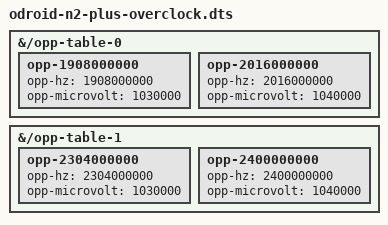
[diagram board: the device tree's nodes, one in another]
/dts-v1/;
/plugin/;

/ {
	fragment@0 {
		target-path = "/opp-table-0";
		__overlay__ {
			opp-1908000000 {
				opp-hz = /bits/ 64 <1908000000>;
				opp-microvolt = <1030000>;
			};
			opp-2016000000 {
				opp-hz = /bits/ 64 <2016000000>;
				opp-microvolt = <1040000>;
			};
		};
	};
	fragment@1 {
		target-path = "/opp-table-1"; 
		__overlay__ {
			opp-2304000000 {
				opp-hz = /bits/ 64 <2304000000>;
				opp-microvolt = <1030000>;
			};
			opp-2400000000 {
				opp-hz = /bits/ 64 <2400000000>;
				opp-microvolt = <1040000>;
			};
		};
	};

};

